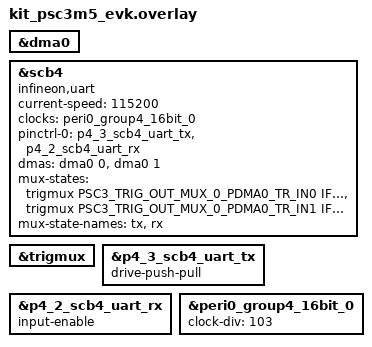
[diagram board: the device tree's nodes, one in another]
/*
 * SPDX-FileCopyrightText: Copyright (c) 2026 Infineon Technologies AG,
 * SPDX-FileCopyrightText: or an affiliate of Infineon Technologies AG. All rights reserved.
 *
 * SPDX-License-Identifier: Apache-2.0
 */

&dma0 {
	status = "okay";
};

dut: &scb4 {
	compatible = "infineon,uart";
	status = "okay";
	current-speed = <115200>;

	clocks = <&peri0_group4_16bit_0>;

	pinctrl-0 = <&p4_3_scb4_uart_tx &p4_2_scb4_uart_rx>;
	pinctrl-names = "default";

	dmas = <&dma0 0>, <&dma0 1>;
	dma-names = "tx", "rx";
	mux-states = <&trigmux PSC3_TRIG_OUT_MUX_0_PDMA0_TR_IN0 IFX_TRIGMUX_EDGE
		      PSC3_TRIG_IN_MUX_0_SCB_TX4>,
		     <&trigmux PSC3_TRIG_OUT_MUX_0_PDMA0_TR_IN1 IFX_TRIGMUX_LEVEL
		      PSC3_TRIG_IN_MUX_0_SCB_RX4>;
	mux-state-names = "tx", "rx";
};

&trigmux {
	status = "okay";
};

&p4_3_scb4_uart_tx {
	drive-push-pull;
};

&p4_2_scb4_uart_rx {
	input-enable;
};

&peri0_group4_16bit_0 {
	status = "okay";
	clock-div = <103>;
};
